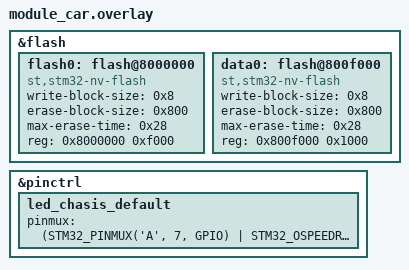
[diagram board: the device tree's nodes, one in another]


/ {

};

&flash {
    flash0: flash@8000000 {
        compatible = "st,stm32-nv-flash", "soc-nv-flash";
        write-block-size = < 0x8 >;
        erase-block-size = < 0x800 >;
        max-erase-time = < 0x28 >;
        reg = < 0x8000000 0xf000 >;
    };

    data0: flash@800f000 {
        compatible = "st,stm32-nv-flash", "soc-nv-flash";
        write-block-size = < 0x8 >;
        erase-block-size = < 0x800 >;
        max-erase-time = < 0x28 >;
        reg = < 0x800f000 0x1000 >;
    };
};

&pinctrl {
    // led_head_0_default: led_head_0_default {
    //     pinmux = <(STM32_PINMUX('B', 0, GPIO) | STM32_OSPEEDR_VERY_HIGH_SPEED)>;
    // };

    // led_head_1_default: led_head_1_default {
    //     pinmux = <(STM32_PINMUX('B', 1, GPIO) | STM32_OSPEEDR_VERY_HIGH_SPEED)>;
    // };

    // led_tail_0_default: led_tail_0_default {
    //     pinmux = <(STM32_PINMUX('A', 6, GPIO) | STM32_OSPEEDR_VERY_HIGH_SPEED)>;
    // };

    // led_tail_1_default: led_tail_1_default {
    //     pinmux = <(STM32_PINMUX('A', 5, GPIO) | STM32_OSPEEDR_VERY_HIGH_SPEED)>;
    // };

    led_chasis_default: led_chasis_default {
        pinmux = <(STM32_PINMUX('A', 7, GPIO) | STM32_OSPEEDR_VERY_HIGH_SPEED)>;
    };
    
    // led_fire_default: led_fire_default {
    //     pinmux = <(STM32_PINMUX('A', 4, GPIO) | STM32_OSPEEDR_VERY_HIGH_SPEED)>;
    // };
};
